# R7FA4W1AD register map
Vendor: Renesas; Series: RA4; File version: 1.0
CPU: CM4 r0p1, little endian, MPU, FPU, VTOR, 4 interrupt priority bits
Registers are 8-bit, read-write, reset 0x0 unless marked. A register's access mark holds for its fields unless they carry their own. Offsets are from the block's base; [hi:lo] are bit positions; 'fields as' and 'values as' point back to an identical list.

## MSTP — Module Stop Control B,C,D
Base 0x40047000
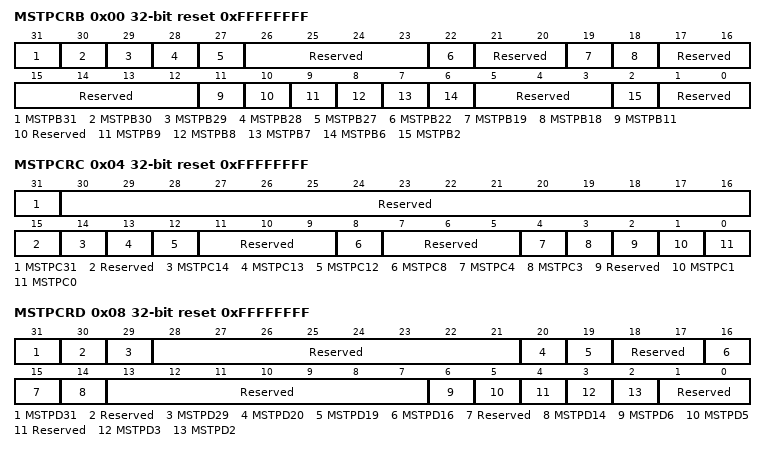
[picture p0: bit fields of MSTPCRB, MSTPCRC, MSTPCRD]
0x00 MSTPCRB 32-bit reset 0xFFFFFFFF — Module Stop Control Register B
  [31] MSTPB31 — Serial Communication Interface 0 Module Stop
    0=Cancel the module-stop state; 1=Enter the module-stop state
  [30] MSTPB30 — Serial Communication Interface 1 Module Stop
    values as MSTPB31
  [29] MSTPB29 — Serial Communication Interface 2 Module Stop
    values as MSTPB31
  [28] MSTPB28 — Serial Communication Interface 3 Module Stop
    values as MSTPB31
  [27] MSTPB27 — Serial Communication Interface 4 Module Stop
    values as MSTPB31
  [26:23] Reserved — These bits are read as 1111. The write value should be 1111.
  [22] MSTPB22 — Serial Communication Interface 9 Module Stop
    values as MSTPB31
  [21:20] Reserved — These bits are read as 11. The write value should be 11.
  [19] MSTPB19 — Serial Peripheral Interface 0 Module Stop
    values as MSTPB31
  [18] MSTPB18 — Serial Peripheral Interface 1 Module Stop
    values as MSTPB31
  [17:12] Reserved — These bits are read as 111111. The write value should be 111111.
  [11] MSTPB11 — Universal Serial Bus 2.0 FS Interface Module Stop
    values as MSTPB31
  [10] Reserved — This bit is read as 1. The write value should be 1.
  [9] MSTPB9 — I2C Bus Interface 0 Module Stop
    values as MSTPB31
  [8] MSTPB8 — I2C Bus Interface 1 Module Stop
    values as MSTPB31
  [7] MSTPB7 — I2C Bus Interface 2 Module Stop
    values as MSTPB31
  [6] MSTPB6 — Queued Serial Peripheral Interface Module Stop
    values as MSTPB31
  [5:3] Reserved — These bits are read as 111. The write value should be 111.
  [2] MSTPB2 — Controller Area Network Module Stop
    values as MSTPB31
  [1:0] Reserved — These bits are read as 11. The write value should be 11.
0x04 MSTPCRC 32-bit reset 0xFFFFFFFF — Module Stop Control Register C
  [31] MSTPC31 — TSIP Module Stop
    values as MSTPCRB.MSTPB31
  [30:15] Reserved — These bits are read as 1111111111111111. The write value should be 1111111111111111.
  [14] MSTPC14 — Event Link Controller Module Stop
    values as MSTPCRB.MSTPB31
  [13] MSTPC13 — Data Operation Circuit Module Stop
    values as MSTPCRB.MSTPB31
  [12] MSTPC12 — Secure Digital Host Interface/Multi Media Card Interface ModuleStop
    values as MSTPCRB.MSTPB31
  [11:9] Reserved — These bits are read as 111. The write value should be 111.
  [8] MSTPC8 — Synchronous Serial Interface 0 Module Stop
    values as MSTPCRB.MSTPB31
  [7:5] Reserved — These bits are read as 111. The write value should be 111.
  [4] MSTPC4 — Segment LCD Controller Module Stop
    values as MSTPCRB.MSTPB31
  [3] MSTPC3 — Capacitive Touch Sensing Unit Module Stop
    values as MSTPCRB.MSTPB31
  [2] Reserved — This bit is read as 1. The write value should be 1.
  [1] MSTPC1 — Cyclic Redundancy Check Calculator Module Stop
    values as MSTPCRB.MSTPB31
  [0] MSTPC0 — Clock Frequency Accuracy Measurement Circuit Module Stop
    values as MSTPCRB.MSTPB31
0x08 MSTPCRD 32-bit reset 0xFFFFFFFF — Module Stop Control Register D
  [31] MSTPD31 — Operational Amplifier Module Stop
    values as MSTPCRB.MSTPB31
  [30] Reserved — This bit is read as 1. The write value should be 1.
  [29] MSTPD29 — Low-Power Analog Comparator Module Stop
    values as MSTPCRB.MSTPB31
  [28:21] Reserved — These bits are read as 11111111. The write value should be 11111111.
  [20] MSTPD20 — 12-Bit D/A Converter Module Stop
    values as MSTPCRB.MSTPB31
  [19] MSTPD19 — 8-bit D/A Converter Module Stop
    values as MSTPCRB.MSTPB31
  [18:17] Reserved — These bits are read as 11. The write value should be 11.
  [16] MSTPD16 — 14-Bit A/D Converter Module Stop
    values as MSTPCRB.MSTPB31
  [15] Reserved — This bit is read as 1. The write value should be 1.
  [14] MSTPD14 — Port Output Enable for GPT Module Stop
    values as MSTPCRB.MSTPB31
  [13:7] Reserved — These bits are read as 1111111. The write value should be 1111111.
  [6] MSTPD6 — General PWM Timer 169 to 164 Module Stop
    values as MSTPCRB.MSTPB31
  [5] MSTPD5 — General PWM Timer 323 to 320 Module Stop
    values as MSTPCRB.MSTPB31
  [4] Reserved — This bit is read as 1. The write value should be 1.
  [3] MSTPD3 — Asynchronous General Purpose Timer 0 Module Stop
    values as MSTPCRB.MSTPB31
  [2] MSTPD2 — Asynchronous General Purpose Timer 1 Module Stop
    values as MSTPCRB.MSTPB31
  [1:0] Reserved — These bits are read as 11. The write value should be 11.
